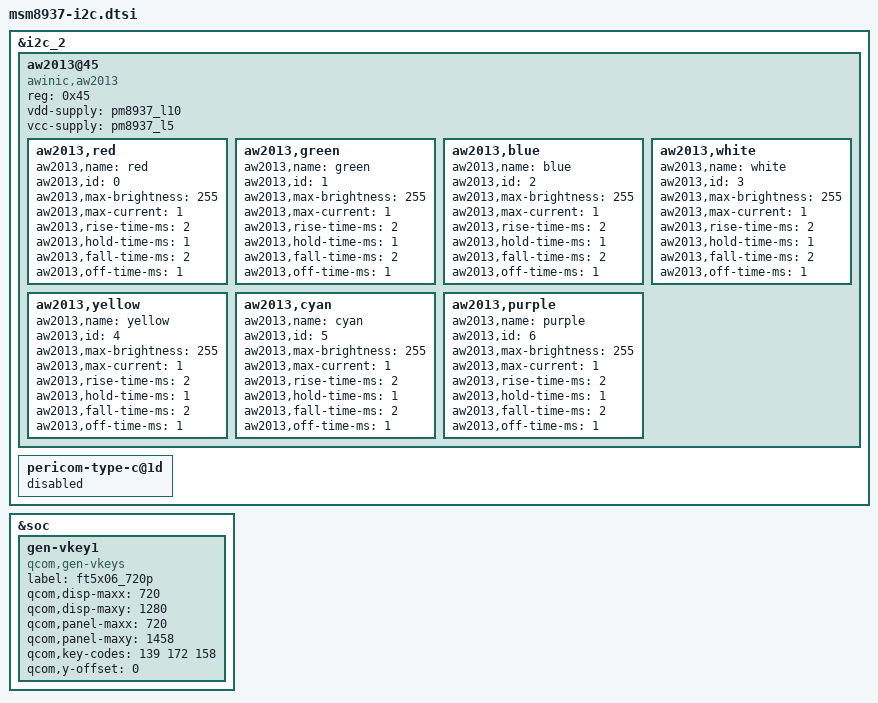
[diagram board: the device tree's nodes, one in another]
&i2c_2  {
	aw2013@45 {
		compatible = "awinic,aw2013";
		reg = <0x45>;
		vdd-supply = <&pm8937_l10>; //Power supply needed to power up the device
		vcc-supply = <&pm8937_l5>; //Power source required to power up i2c bus

		aw2013,red {
			aw2013,name = "red";
			aw2013,id = <0>;
			aw2013,max-brightness = <255>;
			aw2013,max-current = <1>;
			aw2013,rise-time-ms = <2>;
			aw2013,hold-time-ms = <1>;
			aw2013,fall-time-ms = <2>;
			aw2013,off-time-ms = <1>;
		};
		aw2013,green {
			aw2013,name = "green";
			aw2013,id = <1>;
			aw2013,max-brightness = <255>;
			aw2013,max-current = <1>;
			aw2013,rise-time-ms = <2>;
			aw2013,hold-time-ms = <1>;
			aw2013,fall-time-ms = <2>;
			aw2013,off-time-ms = <1>;
		};
		aw2013,blue {
			aw2013,name = "blue";
			aw2013,id = <2>;
			aw2013,max-brightness = <255>;
			aw2013,max-current = <1>;
			aw2013,rise-time-ms = <2>;
			aw2013,hold-time-ms = <1>;
			aw2013,fall-time-ms = <2>;
			aw2013,off-time-ms = <1>;
		};
		aw2013,white {
			aw2013,name = "white";
			aw2013,id = <3>;
			aw2013,max-brightness = <255>;
			aw2013,max-current = <1>;
			aw2013,rise-time-ms = <2>;
			aw2013,hold-time-ms = <1>;
			aw2013,fall-time-ms = <2>;
			aw2013,off-time-ms = <1>;
		};
		aw2013,yellow {
			aw2013,name = "yellow";
			aw2013,id = <4>;
			aw2013,max-brightness = <255>;
			aw2013,max-current = <1>;
			aw2013,rise-time-ms = <2>;
			aw2013,hold-time-ms = <1>;
			aw2013,fall-time-ms = <2>;
			aw2013,off-time-ms = <1>;
		};
		aw2013,cyan {
			aw2013,name = "cyan";
			aw2013,id = <5>;
			aw2013,max-brightness = <255>;
			aw2013,max-current = <1>;
			aw2013,rise-time-ms = <2>;
			aw2013,hold-time-ms = <1>;
			aw2013,fall-time-ms = <2>;
			aw2013,off-time-ms = <1>;
		};
		aw2013,purple {
			aw2013,name = "purple";
			aw2013,id = <6>;
			aw2013,max-brightness = <255>;
			aw2013,max-current = <1>;
			aw2013,rise-time-ms = <2>;
			aw2013,hold-time-ms = <1>;
			aw2013,fall-time-ms = <2>;
			aw2013,off-time-ms = <1>;
		};
	};

        pericom-type-c@1d {
                status="disabled";
        };
};

&soc {
	gen-vkey1 {
		compatible = "qcom,gen-vkeys";
		label = "ft5x06_720p";
		qcom,disp-maxx = <720>;
		qcom,disp-maxy = <1280>;
		qcom,panel-maxx = <720>;
		qcom,panel-maxy = <1458>;
		qcom,key-codes = <139 172 158>;
		qcom,y-offset = <0>;
	};
};
